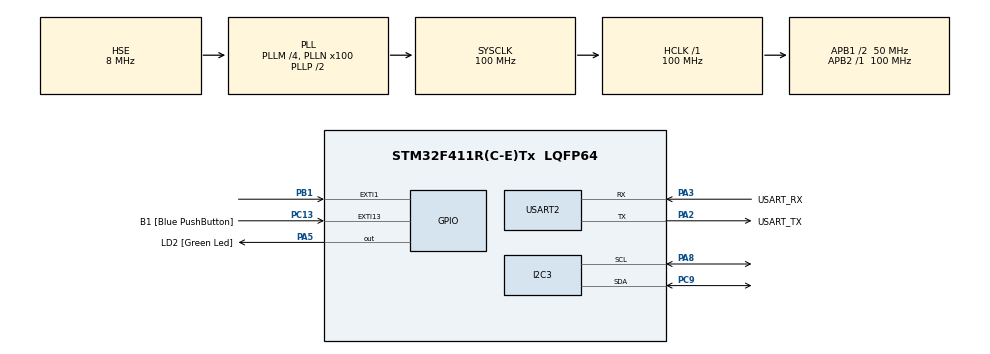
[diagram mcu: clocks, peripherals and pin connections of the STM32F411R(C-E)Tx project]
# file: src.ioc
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Dma.I2C3_RX.0.Direction=DMA_PERIPH_TO_MEMORY
Dma.I2C3_RX.0.FIFOMode=DMA_FIFOMODE_DISABLE
Dma.I2C3_RX.0.Instance=DMA1_Stream1
Dma.I2C3_RX.0.MemDataAlignment=DMA_MDATAALIGN_BYTE
Dma.I2C3_RX.0.MemInc=DMA_MINC_ENABLE
Dma.I2C3_RX.0.Mode=DMA_NORMAL
Dma.I2C3_RX.0.PeriphDataAlignment=DMA_PDATAALIGN_BYTE
Dma.I2C3_RX.0.PeriphInc=DMA_PINC_DISABLE
Dma.I2C3_RX.0.Priority=DMA_PRIORITY_LOW
Dma.I2C3_TX.1.Direction=DMA_MEMORY_TO_PERIPH
Dma.I2C3_TX.1.FIFOMode=DMA_FIFOMODE_DISABLE
Dma.I2C3_TX.1.Instance=DMA1_Stream4
Dma.I2C3_TX.1.MemDataAlignment=DMA_MDATAALIGN_BYTE
Dma.I2C3_TX.1.MemInc=DMA_MINC_ENABLE
Dma.I2C3_TX.1.Mode=DMA_NORMAL
Dma.I2C3_TX.1.PeriphDataAlignment=DMA_PDATAALIGN_BYTE
Dma.I2C3_TX.1.PeriphInc=DMA_PINC_DISABLE
Dma.I2C3_TX.1.Priority=DMA_PRIORITY_LOW
Dma.Request0=I2C3_RX
Dma.Request1=I2C3_TX
I2C3.I2C_Mode=I2C_Fast
Mcu.Family=STM32F4
Mcu.Name=STM32F411R(C-E)Tx
Mcu.Package=LQFP64
NVIC.DMA1_Stream1_IRQn=true\:0\:0\:false\:false\:true\:false\:true\:true
NVIC.DMA1_Stream4_IRQn=true\:0\:0\:false\:false\:true\:false\:true\:true
NVIC.I2C3_ER_IRQn=true\:0\:0\:false\:false\:true\:true\:true\:true
NVIC.I2C3_EV_IRQn=true\:0\:0\:false\:false\:true\:true\:true\:true
NVIC.PriorityGroup=NVIC_PRIORITYGROUP_0
NVIC.RCC_IRQn=true\:0\:0\:false\:false\:true\:true\:false\:true
NVIC.TIM1_BRK_TIM9_IRQn=true\:0\:0\:false\:false\:true\:false\:true\:true
NVIC.TimeBase=TIM1_BRK_TIM9_IRQn
NVIC.TimeBaseIP=TIM9
PA13.GPIO_Label=TMS
PA13.Mode=Trace_Asynchronous_SW
PA13.Signal=SYS_JTMS-SWDIO
PA14.GPIO_Label=TCK
PA14.Mode=Trace_Asynchronous_SW
PA14.Signal=SYS_JTCK-SWCLK
PA2.GPIO_Label=USART_TX
PA2.Mode=Asynchronous
PA2.Signal=USART2_TX
PA3.GPIO_Label=USART_RX
PA3.Mode=Asynchronous
PA3.Signal=USART2_RX
PA5.GPIO_Label=LD2 [Green Led]
PA5.Signal=GPIO_Output
PA8.Mode=I2C
PA8.Signal=I2C3_SCL
PB1.Signal=GPXTI1
PB3.GPIO_Label=SWO
PB3.Mode=Trace_Asynchronous_SW
PB3.Signal=SYS_JTDO-SWO
PC13-ANTI_TAMP.GPIO_Label=B1 [Blue PushButton]
PC13-ANTI_TAMP.GPIO_ModeDefaultEXTI=GPIO_MODE_IT_FALLING
PC13-ANTI_TAMP.Signal=GPXTI13
PC14-OSC32_IN.Mode=LSE-External-Oscillator
PC14-OSC32_IN.Signal=RCC_OSC32_IN
PC15-OSC32_OUT.Mode=LSE-External-Oscillator
PC15-OSC32_OUT.Signal=RCC_OSC32_OUT
PC9.Mode=I2C
PC9.Signal=I2C3_SDA
PH0\ -\ OSC_IN.Mode=HSE-External-Clock-Source
PH0\ -\ OSC_IN.Signal=RCC_OSC_IN
PH1\ -\ OSC_OUT.Mode=HSE-External-Clock-Source
PH1\ -\ OSC_OUT.Signal=RCC_OSC_OUT
ProjectManager.HeapSize=0x200
ProjectManager.StackSize=0x400
ProjectManager.TargetToolchain=CMake
RCC.48MHZClocksFreq_Value=50000000
RCC.AHBFreq_Value=100000000
RCC.APB1CLKDivider=RCC_HCLK_DIV2
RCC.APB1Freq_Value=50000000
RCC.APB1TimFreq_Value=100000000
RCC.APB2Freq_Value=100000000
RCC.APB2TimFreq_Value=100000000
RCC.CortexFreq_Value=100000000
RCC.FLatency-AdvancedSettings=FLASH_LATENCY_3
RCC.HCLKFreq_Value=100000000
RCC.HSE_VALUE=8000000
RCC.HSI_VALUE=16000000
RCC.PLLM=4
RCC.PLLN=100
RCC.PLLSourceVirtual=RCC_PLLSOURCE_HSE
RCC.SYSCLKFreq_VALUE=100000000
RCC.SYSCLKSource=RCC_SYSCLKSOURCE_PLLCLK
RCC.VCOOutputFreq_Value=200000000
USART2.VirtualMode=VM_ASYNC
VP_SYS_VS_tim9.Mode=TIM9
board=NUCLEO-F411RE

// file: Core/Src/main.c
/* USER CODE BEGIN Header */
/**
  ******************************************************************************
  * @file           : main.c
  * @brief          : Main program body
  ******************************************************************************
  * @attention
  *
  * Copyright (c) 2026 STMicroelectronics.
  * All rights reserved.
  *
  * This software is licensed under terms that can be found in the LICENSE file
  * in the root directory of this software component.
  * If no LICENSE file comes with this software, it is provided AS-IS.
  *
  ******************************************************************************
  */
/* USER CODE END Header */
#include "main.h"
#include "dma.h"
#include "i2c.h"
#include "usart.h"
#include "gpio.h"

/* USER CODE BEGIN Includes */
#include "MPU9250.h"
#include "EKF.h"
/* USER CODE END Includes */

void SystemClock_Config(void);

int main(void)
{

  /* MCU Configuration--------------------------------------------------------*/

  /* Reset of all peripherals, Initializes the Flash interface and the Systick. */
  HAL_Init();

  /* Configure the system clock */
  SystemClock_Config();

  /* Initialize all configured peripherals */
  MX_GPIO_Init();
  MX_DMA_Init();
  MX_USART2_UART_Init();
  MX_I2C3_Init();

  /* Infinite loop */
  while (1)
  {

  }
}

void SystemClock_Config(void)
{
  RCC_OscInitTypeDef RCC_OscInitStruct = {0};
  RCC_ClkInitTypeDef RCC_ClkInitStruct = {0};

  /** Configure the main internal regulator output voltage
  */
  __HAL_RCC_PWR_CLK_ENABLE();
  __HAL_PWR_VOLTAGESCALING_CONFIG(PWR_REGULATOR_VOLTAGE_SCALE1);

  /** Initializes the RCC Oscillators according to the specified parameters
  * in the RCC_OscInitTypeDef structure.
  */
  RCC_OscInitStruct.OscillatorType = RCC_OSCILLATORTYPE_HSE;
  RCC_OscInitStruct.HSEState = RCC_HSE_BYPASS;
  RCC_OscInitStruct.PLL.PLLState = RCC_PLL_ON;
  RCC_OscInitStruct.PLL.PLLSource = RCC_PLLSOURCE_HSE;
  RCC_OscInitStruct.PLL.PLLM = 4;
  RCC_OscInitStruct.PLL.PLLN = 100;
  RCC_OscInitStruct.PLL.PLLP = RCC_PLLP_DIV2;
  RCC_OscInitStruct.PLL.PLLQ = 4;
  if (HAL_RCC_OscConfig(&RCC_OscInitStruct) != HAL_OK)
  {
    Error_Handler();
  }

  /** Initializes the CPU, AHB and APB buses clocks
  */
  RCC_ClkInitStruct.ClockType = RCC_CLOCKTYPE_HCLK|RCC_CLOCKTYPE_SYSCLK
                              |RCC_CLOCKTYPE_PCLK1|RCC_CLOCKTYPE_PCLK2;
  RCC_ClkInitStruct.SYSCLKSource = RCC_SYSCLKSOURCE_PLLCLK;
  RCC_ClkInitStruct.AHBCLKDivider = RCC_SYSCLK_DIV1;
  RCC_ClkInitStruct.APB1CLKDivider = RCC_HCLK_DIV2;
  RCC_ClkInitStruct.APB2CLKDivider = RCC_HCLK_DIV1;

  if (HAL_RCC_ClockConfig(&RCC_ClkInitStruct, FLASH_LATENCY_3) != HAL_OK)
  {
    Error_Handler();
  }
}

void HAL_TIM_PeriodElapsedCallback(TIM_HandleTypeDef *htim)
{
  if (htim->Instance == TIM9)
  {
    HAL_IncTick();
  }
}

void Error_Handler(void)
{
  __disable_irq();
  while (1)
  {
  }
}
